# STM32U575 register map
File version: 1.4
CPU: CM33 r0p1, little endian, MPU, FPU, 4 interrupt priority bits
Registers are 32-bit, read-write, reset 0x0 unless marked. A register's access mark holds for its fields unless they carry their own. Offsets are from the block's base; [hi:lo] are bit positions; {n}, {i} and the like mark numbered series; <NAME> marks a mode.

## RCC (part 2 of 4) — Reset and clock control
Base 0x46020C00
Same registers: SEC_RCC 0x56020C00
0x48 RCC_PLL3FRACR — RCC PLL3 fractional divider register
  [15:3] PLL3FRACN — Fractional part of the multiplication factor for PLL3 VCO This bitfield is set and reset by software to control the fractional part of the VCO multiplication factor. It can be written at any time, allowing dynamic fine-tuning of the PLL3 VCO. VCO output frequency = F<sub>ref3_ck</sub> x (PLL3N + (PLL3FRACN / 2<sup>13</sup>)), with: PLL3N must be between 4 and 512. PLL3FRACN can be between 0 and 2<sup>13 </sup>- 1. The input frequency F<sub>ref3_ck</sub> must be between 4 and 16 MHz. In order to change the FRACN value on-the-fly even if the PLL is enabled, the application must proceed as follows: Set the bit PLL3FRACEN to 0. Write the new fractional value into PLL3FRACN. Set the bit PLL3FRACEN to 1.
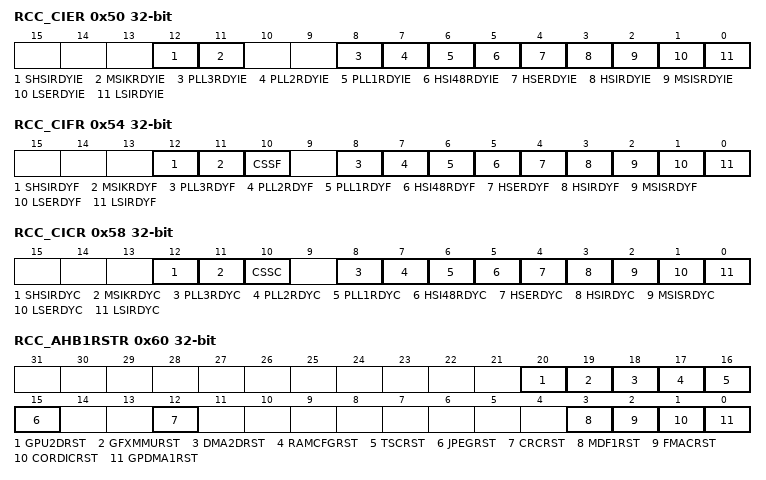
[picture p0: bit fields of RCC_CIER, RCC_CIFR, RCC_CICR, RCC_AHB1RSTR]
0x50 RCC_CIER — RCC clock interrupt enable register
  [12] SHSIRDYIE — SHSI ready interrupt enable This bit is set and cleared by software to enable/disable interrupt caused by the SHSI oscillator stabilization.
    0=SHSI ready interrupt disabled; 1=SHSI ready interrupt enabled
  [11] MSIKRDYIE — MSIK ready interrupt enable This bit is set and cleared by software to enable/disable interrupt caused by the MSIK oscillator stabilization.
    0=MSIK ready interrupt disabled; 1=MSIK ready interrupt enabled
  [8] PLL3RDYIE — PLL3 ready interrupt enable This bit is set and cleared by software to enable/disable interrupt caused by PLL3 lock.
    0=PLL3 lock interrupt disabled; 1=PLL3 lock interrupt enabled
  [7] PLL2RDYIE — PLL2 ready interrupt enable This bit is set and cleared by software to enable/disable interrupt caused by PLL2 lock.
    0=PLL2 lock interrupt disabled; 1=PLL2 lock interrupt enabled
  [6] PLL1RDYIE — PLL ready interrupt enable This bit is set and cleared by software to enable/disable interrupt caused by PLL1 lock.
    0=PLL1 lock interrupt disabled; 1=PLL1 lock interrupt enabled
  [5] HSI48RDYIE — HSI48 ready interrupt enable This bit is set and cleared by software to enable/disable interrupt caused by the HSI48 oscillator stabilization.
    0=HSI48 ready interrupt disabled; 1=HSI48 ready interrupt enabled
  [4] HSERDYIE — HSE ready interrupt enable This bit is set and cleared by software to enable/disable interrupt caused by the HSE oscillator stabilization.
    0=HSE ready interrupt disabled; 1=HSE ready interrupt enabled
  [3] HSIRDYIE — HSI16 ready interrupt enable This bit is set and cleared by software to enable/disable interrupt caused by the HSI16 oscillator stabilization.
    0=HSI16 ready interrupt disabled; 1=HSI16 ready interrupt enabled
  [2] MSISRDYIE — MSIS ready interrupt enable This bit is set and cleared by software to enable/disable interrupt caused by the MSIS oscillator stabilization.
    0=MSIS ready interrupt disabled; 1=MSIS ready interrupt enabled
  [1] LSERDYIE — LSE ready interrupt enable This bit is set and cleared by software to enable/disable interrupt caused by the LSE oscillator stabilization.
    0=LSE ready interrupt disabled; 1=LSE ready interrupt enabled
  [0] LSIRDYIE — LSI ready interrupt enable This bit is set and cleared by software to enable/disable interrupt caused by the LSI oscillator stabilization.
    0=LSI ready interrupt disabled; 1=LSI ready interrupt enabled
0x54 RCC_CIFR ro — RCC clock interrupt flag register
  [12] SHSIRDYF — SHSI ready interrupt flag This bit is set by hardware when the SHSI clock becomes stable and SHSIRDYIE is set. It is cleared by software by setting the SHSIRDYC bit.
    0=No clock ready interrupt caused by the SHSI oscillator; 1=Clock ready interrupt caused by the SHSI oscillator
  [11] MSIKRDYF — MSIK ready interrupt flag This bit is set by hardware when the MSIK clock becomes stable and MSIKRDYIE is set. It is cleared by software by setting the MSIKRDYC bit.
    0=No clock ready interrupt caused by the MSIK oscillator; 1=Clock ready interrupt caused by the MSIK oscillator
  [10] CSSF — Clock security system interrupt flag This bit is set by hardware when a failure is detected in the HSE oscillator. It is cleared by software by setting the CSSC bit.
    0=No clock security interrupt caused by HSE clock failure; 1=Clock security interrupt caused by HSE clock failure
  [8] PLL3RDYF — PLL3 ready interrupt flag This bit is set by hardware when the PLL3 locks and PLL3RDYIE is set. It is cleared by software by setting the PLL3RDYC bit.
    0=No clock ready interrupt caused by PLL3 lock; 1=Clock ready interrupt caused by PLL3 lock
  [7] PLL2RDYF — PLL2 ready interrupt flag This bit is set by hardware when the PLL2 locks and PLL2RDYIE is set. It is cleared by software by setting the PLL2RDYC bit.
    0=No clock ready interrupt caused by PLL2 lock; 1=Clock ready interrupt caused by PLL2 lock
  [6] PLL1RDYF — PLL1 ready interrupt flag This bit is set by hardware when the PLL1 locks and PLL1RDYIE is set. It is cleared by software by setting the PLL1RDYC bit.
    0=No clock ready interrupt caused by PLL1 lock; 1=Clock ready interrupt caused by PLL1 lock
  [5] HSI48RDYF — HSI48 ready interrupt flag This bit is set by hardware when the HSI48 clock becomes stable and HSI48RDYIE is set. it�is cleared by software by setting the HSI48RDYC bit.
    0=No clock ready interrupt caused by the HSI48 oscillator; 1=Clock ready interrupt caused by the HSI48 oscillator
  [4] HSERDYF — HSE ready interrupt flag This bit is set by hardware when the HSE clock becomes stable and HSERDYIE is set. It is cleared by software by setting the HSERDYC bit.
    0=No clock ready interrupt caused by the HSE oscillator; 1=Clock ready interrupt caused by the HSE oscillator
  [3] HSIRDYF — HSI16 ready interrupt flag This bit is set by hardware when the HSI16 clock becomes stable and HSIRDYIE = 1 in�response to setting the HSION (see RCC_CR). When HSION = 0 but the HSI16 oscillator is enabled by the peripheral through a clock request, this bit is not set and no interrupt is generated. This bit is cleared by software by setting the HSIRDYC bit.
    0=No clock ready interrupt caused by the HSI16 oscillator; 1=Clock ready interrupt caused by the HSI16 oscillator
  [2] MSISRDYF — MSIS ready interrupt flag This bit is set by hardware when the MSIS clock becomes stable and MSISRDYIE is set. It�is cleared by software by setting the MSISRDYC bit.
    0=No clock ready interrupt caused by the MSIS oscillator; 1=Clock ready interrupt caused by the MSIS oscillator
  [1] LSERDYF — LSE ready interrupt flag This bit is set by hardware when the LSE clock becomes stable and LSERDYIE is set. It is cleared by software by setting the LSERDYC bit.
    0=No clock ready interrupt caused by the LSE oscillator; 1=Clock ready interrupt caused by the LSE oscillator
  [0] LSIRDYF — LSI ready interrupt flag This bit is set by hardware when the LSI clock becomes stable and LSIRDYIE is set. It is cleared by software by�setting the LSIRDYC bit.
    0=No clock ready interrupt caused by the LSI oscillator; 1=Clock ready interrupt caused by the LSI oscillator
0x58 RCC_CICR wo — RCC clock interrupt clear register
  [12] SHSIRDYC — SHSI oscillator ready interrupt clear Writing this bit to 1 clears the SHSIRDYF flag. Writing 0 has no effect.
  [11] MSIKRDYC — MSIK oscillator ready interrupt clear Writing this bit to 1 clears the MSIKRDYF flag. Writing 0 has no effect.
  [10] CSSC — Clock security system interrupt clear Writing this bit to 1 clears the CSSF flag. Writing 0 has no effect.
  [8] PLL3RDYC — PLL3 ready interrupt clear Writing this bit to 1 clears the PLL3RDYF flag. Writing 0 has no effect.
  [7] PLL2RDYC — PLL2 ready interrupt clear Writing this bit to 1 clears the PLL2RDYF flag. Writing 0 has no effect.
  [6] PLL1RDYC — PLL1 ready interrupt clear Writing this bit to 1 clears the PLL1RDYF flag. Writing 0 has no effect.
  [5] HSI48RDYC — HSI48 ready interrupt clear Writing this bit to 1 clears the HSI48RDYF flag. Writing 0 has no effect.
  [4] HSERDYC — HSE ready interrupt clear Writing this bit to 1 clears the HSERDYF flag. Writing 0 has no effect.
  [3] HSIRDYC — HSI16 ready interrupt clear Writing this bit to 1 clears the HSIRDYF flag. Writing 0 has no effect.
  [2] MSISRDYC — MSIS ready interrupt clear Writing this bit to 1 clears the MSISRDYF flag. Writing 0 has no effect.
  [1] LSERDYC — LSE ready interrupt clear Writing this bit to 1 clears the LSERDYF flag. Writing 0 has no effect.
  [0] LSIRDYC — LSI ready interrupt clear Writing this bit to 1 clears the LSIRDYF flag. Writing 0 has no effect.
0x60 RCC_AHB1RSTR — RCC AHB1 peripheral reset register
  [20] GPU2DRST — GPU2D reset This bit is set and cleared by software. Note: This bit is only available on some devices in the STM32U5 Series. Refer to the device datasheet for availability of its associated peripheral. If not present, consider this bit as reserved and keep it at reset value.
    0=No effect; 1=Reset the GPU2D
  [19] GFXMMURST — GFXMMU reset This bit is set and cleared by software. Note: This bit is only available on some devices in the STM32U5 Series. Refer to the device datasheet for availability of its associated peripheral. If not present, consider this bit as reserved and keep it at reset value.
    0=No effect; 1=Reset the GFXMMU
  [18] DMA2DRST — DMA2D reset This bit is set and cleared by software. Note: This bit is only available on some devices in the STM32U5 Series. Refer to the device datasheet for availability of its associated peripheral. If not present, consider this bit as reserved and keep it at reset value.
    0=No effect; 1=Reset the DMA2D
  [17] RAMCFGRST — RAMCFG reset This bit is set and cleared by software.
    0=No effect; 1=Reset the RAMCFG
  [16] TSCRST — TSC reset This bit is set and cleared by software.
    0=No effect; 1=Reset the TSC
  [15] JPEGRST — JPEG reset This bit is set and cleared by software. Note: This bit is only available on some devices in the STM32U5 Series. Refer to the device datasheet for availability of its associated peripheral. If not present, consider this bit as reserved and keep it at reset value.
    0=No effect; 1=Reset the JPEG
  [12] CRCRST — CRC reset This bit is set and cleared by software.
    0=No effect; 1=Reset the CRC
  [3] MDF1RST — MDF1 reset This bit is set and cleared by software.
    0=No effect; 1=Reset the MDF1
  [2] FMACRST — FMAC reset This bit is set and cleared by software.
    0=No effect; 1=Reset the FMAC
  [1] CORDICRST — CORDIC reset This bit is set and cleared by software.
    0=No effect; 1=Reset the CORDIC
  [0] GPDMA1RST — GPDMA1 reset This bit is set and cleared by software.
    0=No effect; 1=Reset the GPDMA1
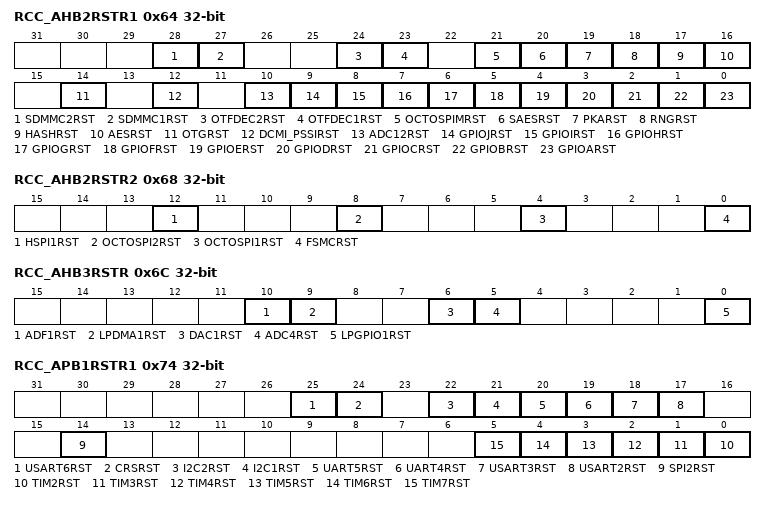
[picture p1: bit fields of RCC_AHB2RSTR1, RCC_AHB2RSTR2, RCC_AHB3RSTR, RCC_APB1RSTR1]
0x64 RCC_AHB2RSTR1 — RCC AHB2 peripheral reset register 1
  [28] SDMMC2RST — SDMMC2 reset This bit is set and cleared by software. Note: This bit is only available on some devices in the STM32U5 Series. Refer to the device datasheet for availability of its associated peripheral. If not present, consider this bit as reserved and keep it at reset value.
    0=No effect; 1=Reset the SDMMC2
  [27] SDMMC1RST — SDMMC1 reset This bit is set and cleared by software.
    0=No effect; 1=Reset the SDMMC1
  [24] OTFDEC2RST — OTFDEC2 reset This bit is set and cleared by software. Note: This bit is only available on some devices in the STM32U5 Series. Refer to the device datasheet for availability of its associated peripheral. If not present, consider this bit as reserved and keep it at reset value.
    0=No effect; 1=Reset the OTFDEC2
  [23] OTFDEC1RST — OTFDEC1 reset This bit is set and cleared by software. Note: This bit is only available on some devices in the STM32U5 Series. Refer to the device datasheet for availability of its associated peripheral. If not present, consider this bit as reserved and keep it at reset value.
    0=No effect; 1=Reset the OTFDEC1
  [21] OCTOSPIMRST — OCTOSPIM reset This bit is set and cleared by software. Note: This bit is only available on some devices in the STM32U5 Series. Refer to the device datasheet for availability of its associated peripheral. If not present, consider this bit as reserved and keep it at reset value.
    0=No effect; 1=Reset the OCTOSPIM
  [20] SAESRST — SAES hardware accelerator reset This bit is set and cleared by software. Note: This bit is only available on some devices in the STM32U5 Series. Refer to the device datasheet for availability of its associated peripheral. If not present, consider this bit as reserved and keep it at reset value.
    0=No effect; 1=Reset the SAES
  [19] PKARST — PKA reset This bit is set and cleared by software. Note: This bit is only available on some devices in the STM32U5 Series. Refer to the device datasheet for availability of its associated peripheral. If not present, consider this bit as reserved and keep it at reset value.
    0=No effect; 1=Reset the PKA
  [18] RNGRST — RNG reset This bit is set and cleared by software.
    0=No effect; 1=Reset the RNG
  [17] HASHRST — HASH reset This bit is set and cleared by software.
    0=No effect; 1=Reset the HASH
  [16] AESRST — AES hardware accelerator reset This bit is set and cleared by software. Note: This bit is only available on some devices in the STM32U5 Series. Refer to the device datasheet for availability of its associated peripheral. If not present, consider this bit as reserved and keep it at reset value.
    0=No effect; 1=Reset the AES
  [14] OTGRST — OTG_FS or OTG_HS reset This bit is set and cleared by software. Note: This bit is only available on some devices in the STM32U5 Series. Refer to the device datasheet for availability of its associated peripheral. If not present, consider this bit as reserved and keep it at reset value.
    0=No effect; 1=Reset the OTG_FS or OTG_HS
  [12] DCMI_PSSIRST — DCMI and PSSI reset This bit is set and cleared by software.
    0=No effect; 1=Reset the DCMI and PSSI
  [10] ADC12RST — ADC1 and ADC2 reset This bit is set and cleared by software. Note: This bit impacts ADC1 in STM32U535/545/575/585, and ADC1/ADC2 in�STM32U59x/5Ax/5Fx/5Gx.
    0=No effect; 1=Reset the ADC1 and ADC2
  [9] GPIOJRST — I/O port J reset This bit is set and cleared by software. Note: This bit is only available on some devices in the STM32U5 Series. Refer to the device datasheet for availability of its associated peripheral. If not present, consider this bit as reserved and keep it at reset value.
    0=No effect; 1=Reset the I/O port J
  [8] GPIOIRST — I/O port I reset This bit is set and cleared by software. Note: This bit is only available on some devices in the STM32U5 Series. Refer to the device datasheet for availability of its associated peripheral. If not present, consider this bit as reserved and keep it at reset value.
    0=No effect; 1=Reset the I/O port .I
  [7] GPIOHRST — I/O port H reset This bit is set and cleared by software.
    0=No effect; 1=Reset the I/O port H
  [6] GPIOGRST — I/O port G reset This bit is set and cleared by software.
    0=No effect; 1=Reset the I/O port G
  [5] GPIOFRST — I/O port F reset This bit is set and cleared by software. This bit is only available on some devices in the STM32U5 Series. Refer to the device datasheet for availability of its associated peripheral. Note: If not present, consider this bit as reserved and keep it at reset value.
    0=No effect; 1=Reset I/O port F
  [4] GPIOERST — I/O port E reset This bit is set and cleared by software.
    0=No effect; 1=Reset the I/O port E
  [3] GPIODRST — I/O port D reset This bit is set and cleared by software.
    0=No effect; 1=Reset the I/O port D
  [2] GPIOCRST — I/O port C reset This bit is set and cleared by software.
    0=No effect; 1=Reset the I/O port C
  [1] GPIOBRST — I/O port B reset This bit is set and cleared by software.
    0=No effect; 1=Reset the I/O port B
  [0] GPIOARST — I/O port A reset This bit is set and cleared by software.
    0=No effect; 1=Reset the I/O port A
0x68 RCC_AHB2RSTR2 — RCC AHB2 peripheral reset register 2
  [12] HSPI1RST — HSPI1 reset This bit is set and cleared by software. Note: This bit is only available on some devices in the STM32U5 Series. Refer to the device datasheet for availability of its associated peripheral. If not present, consider this bit as reserved and keep it at reset value.
    0=No effect; 1=Reset the HSPI1
  [8] OCTOSPI2RST — OCTOSPI2 reset This bit is set and cleared by software. Note: This bit is only available on some devices in the STM32U5 Series. Refer to the device datasheet for availability of its associated peripheral. If not present, consider this bit as reserved and keep it at reset value.
    0=No effect; 1=Reset the OCTOSPI2
  [4] OCTOSPI1RST — OCTOSPI1 reset This bit is set and cleared by software.
    0=No effect; 1=Reset the OCTOSPI1
  [0] FSMCRST — Flexible memory controller reset This bit is set and cleared by software. Note: This bit is only available on some devices in the STM32U5 Series. Refer to the device datasheet for availability of its associated peripheral. If not present, consider this bit as reserved and keep it at reset value.
    0=No effect; 1=Reset the FSMC
0x6C RCC_AHB3RSTR — RCC AHB3 peripheral reset register
  [10] ADF1RST — ADF1 reset This bit is set and cleared by software.
    0=No effect; 1=Reset the ADF1
  [9] LPDMA1RST — LPDMA1 reset This bit is set and cleared by software.
    0=No effect; 1=Reset the LPDMA1
  [6] DAC1RST — DAC1 reset This bit is set and cleared by software.
    0=No effect; 1=Reset the DAC1
  [5] ADC4RST — ADC4 reset This bit is set and cleared by software.
    0=No effect; 1=Reset the ADC4 interface
  [0] LPGPIO1RST — LPGPIO1 reset This bit is set and cleared by software.
    0=No effect; 1=Reset the LPGPIO1
0x74 RCC_APB1RSTR1 — RCC APB1 peripheral reset register 1
  [25] USART6RST — USART6 reset This bit is set and cleared by software. Note: This bit is only available on some devices in the STM32U5 Series. Refer to the device datasheet for availability of its associated peripheral. If not present, consider this bit as reserved and keep it at reset value.
    0=No effect; 1=Reset the USART6
  [24] CRSRST — CRS reset This bit is set and cleared by software.
    0=No effect; 1=Reset the CRS
  [22] I2C2RST — I2C2 reset This bit is set and cleared by software.
    0=No effect; 1=Reset the I2C2
  [21] I2C1RST — I2C1 reset This bit is set and cleared by software.
    0=No effect; 1=Reset the I2C1
  [20] UART5RST — UART5 reset This bit is set and cleared by software.
    0=No effect; 1=Reset the UART5
  [19] UART4RST — UART4 reset This bit is set and cleared by software.
    0=No effect; 1=Reset the UART4
  [18] USART3RST — USART3 reset This bit is set and cleared by software.
    0=No effect; 1=Reset the USART3
  [17] USART2RST — USART2 reset This bit is set and cleared by software. Note: This bit is only available on some devices in the STM32U5 Series.Refer to the device datasheet for availability of its associated peripheral. If not present, consider this bit as reserved and keep it at reset value.
    0=No effect; 1=Reset the USART2
  [14] SPI2RST — SPI2 reset This bit is set and cleared by software.
    0=No effect; 1=Reset the SPI2
  [n-2] TIM{n}RST (n=2..7) — TIM{n} reset This bit is set and cleared by software.
    0=No effect; 1=Reset the TIM{n}
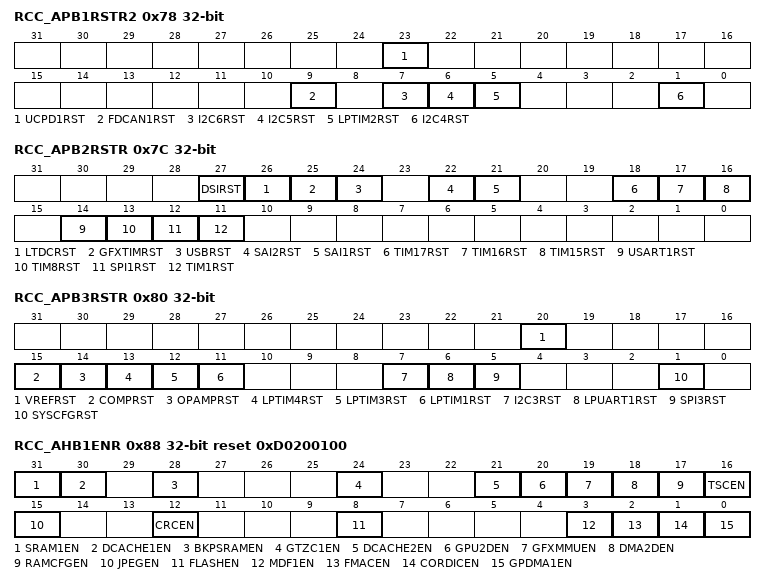
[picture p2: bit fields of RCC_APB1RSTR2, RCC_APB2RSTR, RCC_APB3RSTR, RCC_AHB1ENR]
0x78 RCC_APB1RSTR2 — RCC APB1 peripheral reset register 2
  [23] UCPD1RST — UCPD1 reset This bit is set and cleared by software. Note: This bit is only available on some devices in the STM32U5 Series. Refer to the device datasheet for availability of its associated peripheral. If not present, consider this bit as reserved and keep it at reset value.
    0=No effect; 1=Reset the UCPD1
  [9] FDCAN1RST — FDCAN1 reset This bit is set and cleared by software.
    0=No effect; 1=Reset the FDCAN1
  [7] I2C6RST — I2C6 reset This bit is set and cleared by software Note: This bit is only available on some devices in the STM32U5 Series. Refer to the device datasheet for availability of its associated peripheral. If not present, consider this bit as reserved and keep it at reset value.
    0=No effect; 1=Reset the I2C6
  [6] I2C5RST — I2C5 reset This bit is set and cleared by software Note: This bit is only available on some devices in the STM32U5 Series. Refer to the device datasheet for availability of its associated peripheral. If not present, consider this bit as reserved and keep it at reset value.
    0=No effect; 1=Reset the I2C5
  [5] LPTIM2RST — LPTIM2 reset This bit is set and cleared by software.
    0=No effect; 1=Reset the LPTIM2
  [1] I2C4RST — I2C4 reset This bit is set and cleared by software
    0=No effect; 1=Reset the I2C4
0x7C RCC_APB2RSTR — RCC APB2 peripheral reset register
  [27] DSIRST — DSI reset This bit is set and cleared by software. Note: This bit is only available on some devices in the STM32U5 Series. Refer to the device datasheet for availability of its associated peripheral. If not present, consider this bit as reserved and keep it at reset value.
    0=No effect; 1=Reset the DSI
  [26] LTDCRST — LTDC reset This bit is set and cleared by software. Note: This bit is only available on some devices in the STM32U5 Series. Refer to the device datasheet for availability of its associated peripheral. If not present, consider this bit as reserved and keep it at reset value.
    0=No effect; 1=Reset the LTDC
  [25] GFXTIMRST — GFXTIM reset This bit is set and cleared by software. Note: .This bit is only available on some devices in the STM32U5 Series. Refer to the device datasheet for availability of its associated peripheral. If not present, consider this bit as reserved and keep it at reset value.
    0=No effect; 1=Reset the GFXTIM
  [24] USBRST — USB reset This bit is set and cleared by software. Note: This bit is only available on some devices in the STM32U5 Series. Refer to the device datasheet for availability of its associated peripheral. If not present, consider this bit as reserved and keep it at reset value.
    0=No effect; 1=Reset the USB
  [22] SAI2RST — SAI2 reset This bit is set and cleared by software. Note: This bit is only available on some devices in the STM32U5 Series. Refer to the device datasheet for availability of its associated peripheral. If not present, consider this bit as reserved and keep it at reset value.
    0=No effect; 1=Reset the SAI2
  [21] SAI1RST — SAI1 reset This bit is set and cleared by software.
    0=No effect; 1=Reset the SAI1
  [18] TIM17RST — TIM17 reset This bit is set and cleared by software.
    0=No effect; 1=Reset the TIM17
  [17] TIM16RST — TIM16 reset This bit is set and cleared by software.
    0=No effect; 1=Reset the TIM16
  [16] TIM15RST — TIM15 reset This bit is set and cleared by software.
    0=No effect; 1=Reset the TIM15
  [14] USART1RST — USART1 reset This bit is set and cleared by software.
    0=No effect; 1=Reset the USART1
  [13] TIM8RST — TIM8 reset This bit is set and cleared by software.
    0=No effect; 1=Reset the TIM8
  [12] SPI1RST — SPI1 reset This bit is set and cleared by software.
    0=No effect; 1=Reset the SPI1
  [11] TIM1RST — TIM1 reset This bit is set and cleared by software.
    0=No effect; 1=Reset the TIM1
0x80 RCC_APB3RSTR — RCC APB3 peripheral reset register
  [20] VREFRST — VREFBUF reset This bit is set and cleared by software.
    0=No effect; 1=Reset the VREFBUF
  [15] COMPRST — COMP reset This bit is set and cleared by software.
    0=No effect; 1=Reset the COMP
  [14] OPAMPRST — OPAMP reset This bit is set and cleared by software.
    0=No effect; 1=Reset the OPAMP
  [13] LPTIM4RST — LPTIM4 reset This bit is set and cleared by software.
    0=No effect; 1=Reset the LPTIM4
  [12] LPTIM3RST — LPTIM3 reset This bit is set and cleared by software.
    0=No effect; 1=Reset the LPTIM3
  [11] LPTIM1RST — LPTIM1 reset This bit is set and cleared by software.
    0=No effect; 1=Reset the LPTIM1
  [7] I2C3RST — I2C3 reset This bit is set and cleared by software.
    0=No effect; 1=Reset the I2C3
  [6] LPUART1RST — LPUART1 reset This bit is set and cleared by software.
    0=No effect; 1=Reset the LPUART1
  [5] SPI3RST — SPI3 reset This bit is set and cleared by software.
    0=No effect; 1=Reset the SPI3
  [1] SYSCFGRST — SYSCFG reset This bit is set and cleared by software.
    0=No effect; 1=Reset the SYSCFG
0x88 RCC_AHB1ENR reset 0xD0200100 — RCC AHB1 peripheral clock enable register
  [31] SRAM1EN — SRAM1 clock enable This bit is set and reset by software.
    0=SRAM1 clock disabled; 1=SRAM1 clock enabled
  [30] DCACHE1EN — DCACHE1 clock enable This bit is set and reset by software. Note: DCACHE1 clock must be enabled when external memories are accessed through OCTOSPI1, OCTOSPI2, HSPI1 or FSMC, even if the DCACHE1 is bypassed.
    0=DCACHE1 clock disabled; 1=DCACHE1 clock enabled
  [28] BKPSRAMEN — BKPSRAM clock enable This bit is set and reset by software.
    0=BKPSRAM clock disabled; 1=BKPSRAM clock enabled
  [24] GTZC1EN — GTZC1 clock enable This bit is set and reset by software.
    0=GTZC1 clock disabled; 1=GTZC1 clock enabled
  [21] DCACHE2EN — DCACHE2 clock enable This bit is set and reset by software. Note: DCACHE2 clock must be enabled to access memories, even if the DCACHE2 is bypassed. Note: This bit is only available on some devices in the STM32U5 Series. Refer to the device datasheet for availability of its associated peripheral. If not present, consider this bit as reserved and keep it at reset value.
    0=DCACHE2 clock disabled; 1=DCACHE2 clock enabled
  [20] GPU2DEN — GPU2D clock enable This bit is set and cleared by software. Note: This bit is only available on some devices in the STM32U5 Series. Refer to the device datasheet for availability of its associated peripheral. If not present, consider this bit as reserved and keep it at reset value.
    0=GPU2D clock disabled; 1=GPU2D clock enabled
  [19] GFXMMUEN — GFXMMU clock enable This bit is set and cleared by software. Note: This bit is only available on some devices in the STM32U5 Series. Refer to the device datasheet for availability of its associated peripheral. If not present, consider this bit as reserved and keep it at reset value.
    0=GFXMMU clock disabled; 1=GFXMMU clock enabled
  [18] DMA2DEN — DMA2D clock enable This bit is set and cleared by software. Note: This bit is only available on some devices in the STM32U5 Series. Refer to the device datasheet for availability of its associated peripheral. If not present, consider this bit as reserved and keep it at reset value.
    0=DMA2D clock disabled; 1=DMA2D clock enabled
  [17] RAMCFGEN — RAMCFG clock enable This bit is set and cleared by software.
    0=RAMCFG clock disabled; 1=RAMCFG clock enabled
  [16] TSCEN — Touch sensing controller clock enable This bit is set and cleared by software.
    0=TSC clock disabled; 1=TSC clock enabled
  [15] JPEGEN — JPEG clock enable This bit is set and cleared by software. Note: This bit is only available on some devices in the STM32U5 Series. Refer to the device datasheet for availability of its associated peripheral. If not present, consider this bit as reserved and keep it at reset value.
    0=JPEG clock disabled; 1=JPEG clock enabled
  [12] CRCEN — CRC clock enable This bit is set and cleared by software.
    0=CRC clock disabled; 1=CRC clock enabled
  [8] FLASHEN — FLASH clock enable This bit is set and cleared by software. This bit can be disabled only when the flash memory is in power-down mode.
    0=FLASH clock disabled; 1=FLASH clock enabled
  [3] MDF1EN — MDF1 clock enable This bit is set and reset by software.
    0=MDF1 clock disabled; 1=MDF1 clock enabled
  [2] FMACEN — FMAC clock enable This bit is set and reset by software.
    0=FMAC clock disabled; 1=FMAC clock enabled
  [1] CORDICEN — CORDIC clock enable This bit is set and cleared by software.
    0=CORDIC clock disabled; 1=CORDIC clock enabled
  [0] GPDMA1EN — GPDMA1 clock enable This bit is set and cleared by software.
    0=GPDMA1 clock disabled; 1=GPDMA1 clock enabled
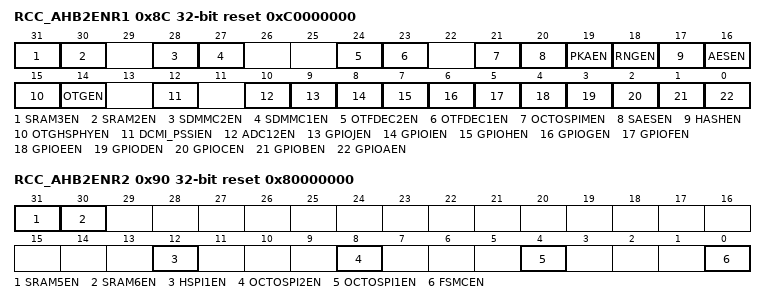
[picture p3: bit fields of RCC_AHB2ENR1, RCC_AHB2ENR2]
0x8C RCC_AHB2ENR1 reset 0xC0000000 — RCC AHB2 peripheral clock enable register 1
  [31] SRAM3EN — SRAM3 clock enable This bit is set and reset by software. Note: This bit is only available on some devices in the STM32U5 Series. Refer to the device datasheet for availability of its associated peripheral. If not present, consider this bit as reserved and keep it at reset value.
    0=SRAM3 clock disabled; 1=SRAM3 clock enabled
  [30] SRAM2EN — SRAM2 clock enable This bit is set and reset by software.
    0=SRAM2 clock disabled; 1=SRAM2 clock enabled
  [28] SDMMC2EN — SDMMC2 clock enable This bit is set and cleared by software. Note: This bit is only available on some devices in the STM32U5 Series. Refer to the device datasheet for availability of its associated peripheral. If not present, consider this bit as reserved and keep it at reset value.
    0=SDMMC2 clock disabled; 1=SDMMC2 clock enabled
  [27] SDMMC1EN — SDMMC1 clock enable This bit is set and cleared by software.
    0=SDMMC1 clock disabled; 1=SDMMC1 clock enabled
  [24] OTFDEC2EN — OTFDEC2 clock enable This bit is set and cleared by software. Note: This bit is only available on some devices in the STM32U5 Series. Refer to the device datasheet for availability of its associated peripheral. If not present, consider this bit as reserved and keep it at reset value.
    0=OTFDEC2 clock disabled; 1=OTFDEC2 clock enabled
  [23] OTFDEC1EN — OTFDEC1 clock enable This bit is set and cleared by software. Note: This bit is only available on some devices in the STM32U5 Series. Refer to the device datasheet for availability of its associated peripheral. If not present, consider this bit as reserved and keep it at reset value.
    0=OTFDEC1 clock disabled; 1=OTFDEC1 clock enabled
  [21] OCTOSPIMEN — OCTOSPIM clock enable This bit is set and cleared by software. Note: This bit is only available on some devices in the STM32U5 Series. Refer to the device datasheet for availability of its associated peripheral. If not present, consider this bit as reserved and keep it at reset value.
    0=OCTOSPIM clock disabled; 1=OCTOSPIM clock enabled
  [20] SAESEN — SAES clock enable This bit is set and cleared by software. Note: This bit is only available on some devices in the STM32U5 Series. Refer to the device datasheet for availability of its associated peripheral. If not present, consider this bit as reserved and keep it at reset value.
    0=SAES clock disabled; 1=SAES clock enabled
  [19] PKAEN — PKA clock enable This bit is set and cleared by software. Note: This bit is only available on some devices in the STM32U5 Series. Refer to the device datasheet for availability of its associated peripheral. If not present, consider this bit as reserved and keep it at reset value.
    0=PKA clock disabled; 1=PKA clock enabled
  [18] RNGEN — RNG clock enable This bit is set and cleared by software.
    0=RNG clock disabled; 1=RNG clock enabled
  [17] HASHEN — HASH clock enable This bit is set and cleared by software
    0=HASH clock disabled; 1=HASH clock enabled
  [16] AESEN — AES clock enable This bit is set and cleared by software. Note: This bit is only available on some devices in the STM32U5 Series. Refer to the device datasheet for availability of its associated peripheral. If not present, consider this bit as reserved and keep it at reset value.
    0=AES clock disabled; 1=AES clock enabled
  [15] OTGHSPHYEN — OTG_HS PHY clock enable This bit is set and cleared by software. Note: This bit is only available on some devices in the STM32U5 Series. Refer to the device datasheet for availability of its associated peripheral. If not present, consider this bit as reserved and keep it at reset value.
    0=OTG_HS PHY clock disabled; 1=OTG_HS PHY clock enabled
  [14] OTGEN — OTG_FS or OTG_HS clock enable This bit is set and cleared by software. Note: This bit is only available on some devices in the STM32U5 Series. Refer to the device datasheet for availability of its associated peripheral. If not present, consider this bit as reserved and keep it at reset value.
    0=OTG_FS or OTG_HS clock disabled; 1=OTG_FS or OTG_HS clock enabled
  [12] DCMI_PSSIEN — DCMI and PSSI clock enable This bit is set and cleared by software.
    0=DCMI and PSSI clock disabled; 1=DCMI and PSSI clock enabled
  [10] ADC12EN — ADC1 and ADC2 clock enable This bit is set and cleared by software. Note: This bit impacts ADC1 in STM32U535/545/575/585, and ADC1/ADC2 in�STM32U59x/5Ax/5Fx/5Gx.
    0=ADC1 and ADC2 clock disabled; 1=ADC1 and ADC2 clock enabled
  [9] GPIOJEN — I/O port J clock enable This bit is set and cleared by software. Note: This bit is only available on some devices in the STM32U5 Series. Refer to the device datasheet for availability of its associated peripheral. If not present, consider this bit as reserved and keep it at reset value.
    0=I/O port J clock disabled; 1=I/O port J clock enabled
  [8] GPIOIEN — I/O port I clock enable This bit is set and cleared by software. Note: This bit is only available on some devices in the STM32U5 Series. Refer to the device datasheet for availability of its associated peripheral. If not present, consider this bit as reserved and keep it at reset value.
    0=I/O port I clock disabled; 1=I/O port I clock enabled
  [7] GPIOHEN — I/O port H clock enable This bit is set and cleared by software.
    0=I/O port H clock disabled; 1=I/O port H clock enabled
  [6] GPIOGEN — I/O port G clock enable This bit is set and cleared by software.
    0=I/O port G clock disabled; 1=I/O port G clock enabled
  [5] GPIOFEN — I/O port F clock enable This bit is set and cleared by software. Note: This bit is only available on some devices in the STM32U5 Series. Refer to the device datasheet for availability of its associated peripheral. If not present, consider this bit as reserved and keep it at reset value.
    0=I/O port F clock disabled; 1=I/O port F clock enabled
  [4] GPIOEEN — I/O port E clock enable This bit is set and cleared by software.
    0=I/O port E clock disabled; 1=I/O port E clock enabled
  [3] GPIODEN — I/O port D clock enable This bit is set and cleared by software.
    0=I/O port D clock disabled; 1=I/O port D clock enabled
  [2] GPIOCEN — I/O port C clock enable This bit is set and cleared by software.
    0=I/O port C clock disabled; 1=I/O port C clock enabled
  [1] GPIOBEN — I/O port B clock enable This bit is set and cleared by software.
    0=I/O port B clock disabled; 1=I/O port B clock enabled
  [0] GPIOAEN — I/O port A clock enable This bit is set and cleared by software.
    0=I/O port A clock disabled; 1=I/O port A clock enabled
0x90 RCC_AHB2ENR2 reset 0x80000000 — RCC AHB2 peripheral clock enable register 2
  [31] SRAM5EN — SRAM5 clock enable This bit is set and reset by software. Note: This bit is only available on some devices in the STM32U5 Series. Refer to the device datasheet for availability of its associated peripheral. If not present, consider this bit as reserved and keep it at reset value.
    0=SRAM5 clock disabled; 1=SRAM5 clock enabled
  [30] SRAM6EN — SRAM6 clock enable This bit is set and reset by software. Note: This bit is only available on some devices in the STM32U5 Series. Refer to the device datasheet for availability of its associated peripheral. If not present, consider this bit as reserved and keep it at reset value.
    0=SRAM6 clock disabled; 1=SRAM6 clock enabled
  [12] HSPI1EN — HSPI1 clock enable This bit is set and cleared by software. Note: This bit is only available on some devices in the STM32U5 Series. Refer to the device datasheet for availability of its associated peripheral. If not present, consider this bit as reserved and keep it at reset value.
    0=HSPI1 clock disabled; 1=HSPI1 clock enabled
  [8] OCTOSPI2EN — OCTOSPI2 clock enable This bit is set and cleared by software. Note: This bit is only available on some devices in the STM32U5 Series. Refer to the device datasheet for availability of its associated peripheral. If not present, consider this bit as reserved and keep it at reset value.
    0=OCTOSPI2 clock disabled; 1=OCTOSPI2 clock enabled
  [4] OCTOSPI1EN — OCTOSPI1 clock enable This bit is set and cleared by software.
    0=OCTOSPI1 clock disabled; 1=OCTOSPI1 clock enabled
  [0] FSMCEN — FSMC clock enable This bit is set and cleared by software. Note: This bit is only available on some devices in the STM32U5 Series. Refer to the device datasheet for availability of its associated peripheral. If not present, consider this bit as reserved and keep it at reset value.
    0=FSMC clock disabled; 1=FSMC clock enabled
